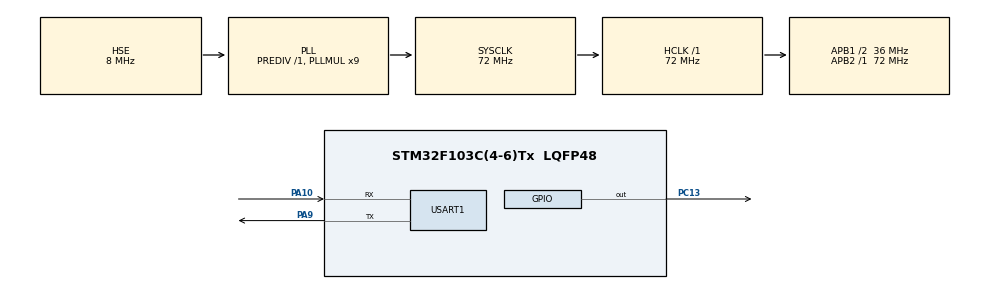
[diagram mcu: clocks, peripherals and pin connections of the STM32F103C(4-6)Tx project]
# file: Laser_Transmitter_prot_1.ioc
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Mcu.Family=STM32F1
Mcu.Name=STM32F103C(4-6)Tx
Mcu.Package=LQFP48
NVIC.PriorityGroup=NVIC_PRIORITYGROUP_4
NVIC.USART1_IRQn=true\:0\:0\:false\:false\:true\:true\:true\:true
PA10.Mode=Asynchronous
PA10.Signal=USART1_RX
PA9.Mode=Asynchronous
PA9.Signal=USART1_TX
PC13-TAMPER-RTC.Signal=GPIO_Output
PD0-OSC_IN.Mode=HSE-External-Oscillator
PD0-OSC_IN.Signal=RCC_OSC_IN
PD1-OSC_OUT.Mode=HSE-External-Oscillator
PD1-OSC_OUT.Signal=RCC_OSC_OUT
ProjectManager.HeapSize=0x200
ProjectManager.StackSize=0x400
ProjectManager.TargetToolchain=STM32CubeIDE
RCC.AHBFreq_Value=72000000
RCC.APB1CLKDivider=RCC_HCLK_DIV2
RCC.APB1Freq_Value=36000000
RCC.APB1TimFreq_Value=72000000
RCC.APB2Freq_Value=72000000
RCC.APB2TimFreq_Value=72000000
RCC.HCLKFreq_Value=72000000
RCC.PLLMUL=RCC_PLL_MUL9
RCC.PLLSourceVirtual=RCC_PLLSOURCE_HSE
RCC.SYSCLKFreq_VALUE=72000000
RCC.SYSCLKSource=RCC_SYSCLKSOURCE_PLLCLK
RCC.USBFreq_Value=72000000
USART1.VirtualMode=VM_ASYNC
VP_SYS_VS_ND.Mode=No_Debug
board=custom

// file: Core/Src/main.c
/* USER CODE BEGIN Header */
/**
  ******************************************************************************
  * @file           : main.c
  * @brief          : Main program body
  ******************************************************************************
  * @attention
  *
  * Copyright (c) 2025 STMicroelectronics.
  * All rights reserved.
  *
  * This software is licensed under terms that can be found in the LICENSE file
  * in the root directory of this software component.
  * If no LICENSE file comes with this software, it is provided AS-IS.
  *
  ******************************************************************************
  */
/* USER CODE END Header */
#include "main.h"

UART_HandleTypeDef huart1;

/* USER CODE BEGIN PV */
char tx_buffer[32];
uint8_t cur_light;
uint8_t rx_indx;
uint8_t rx_data[1];
uint8_t rx_buffer[100];
uint8_t transfer_cplt;
/* USER CODE END PV */

void SystemClock_Config(void);
static void MX_GPIO_Init(void);
static void MX_USART1_UART_Init(void);
/* USER CODE BEGIN PFP */
static void Transmit_message_OOK(uint8_t*, uint8_t);
static void Transmit_message_PPM(uint8_t*, uint8_t);
/* USER CODE END PFP */

int main(void)
{

  /* MCU Configuration--------------------------------------------------------*/

  /* Reset of all peripherals, Initializes the Flash interface and the Systick. */
  HAL_Init();

  /* Configure the system clock */
  SystemClock_Config();

  /* Initialize all configured peripherals */
  MX_GPIO_Init();
  MX_USART1_UART_Init();
  /* USER CODE BEGIN 2 */

  HAL_UART_Receive_IT(&huart1, rx_data, 1);
  /* USER CODE END 2 */

  /* Infinite loop */
  /* USER CODE BEGIN WHILE */
  while (1)
  {
	  HAL_UART_Transmit(&huart1, (unsigned char *)"Please, insert your message\n\r",29 , 10);

	  while (transfer_cplt != 1){
		  HAL_Delay(100);
	  }

	  HAL_UART_Transmit(&huart1, (unsigned char *)"Starting transmission", 21, 5);
	  Transmit_message_PPM(rx_buffer, 100);
	  HAL_Delay(160);
	  HAL_UART_Transmit(&huart1, (unsigned char *)"\n\rTransmission complete\n\r", 25, 5);
	  HAL_GPIO_WritePin(GPIOC, GPIO_PIN_13, 0);
	  transfer_cplt = 0;

	  /*
	  HAL_GPIO_WritePin(GPIOC, GPIO_PIN_13, 1);
	  HAL_Delay(5000);
	  HAL_GPIO_WritePin(GPIOC, GPIO_PIN_13, 0);
	  HAL_Delay(1000);
	  HAL_UART_Transmit(&huart1, "Hello, world!", 13, 5);
	  */
    /* USER CODE END WHILE */

  }
}

void SystemClock_Config(void)
{
  RCC_OscInitTypeDef RCC_OscInitStruct = {0};
  RCC_ClkInitTypeDef RCC_ClkInitStruct = {0};

  /** Initializes the RCC Oscillators according to the specified parameters
  * in the RCC_OscInitTypeDef structure.
  */
  RCC_OscInitStruct.OscillatorType = RCC_OSCILLATORTYPE_HSE;
  RCC_OscInitStruct.HSEState = RCC_HSE_ON;
  RCC_OscInitStruct.HSEPredivValue = RCC_HSE_PREDIV_DIV1;
  RCC_OscInitStruct.HSIState = RCC_HSI_ON;
  RCC_OscInitStruct.PLL.PLLState = RCC_PLL_ON;
  RCC_OscInitStruct.PLL.PLLSource = RCC_PLLSOURCE_HSE;
  RCC_OscInitStruct.PLL.PLLMUL = RCC_PLL_MUL9;
  if (HAL_RCC_OscConfig(&RCC_OscInitStruct) != HAL_OK)
  {
    Error_Handler();
  }

  /** Initializes the CPU, AHB and APB buses clocks
  */
  RCC_ClkInitStruct.ClockType = RCC_CLOCKTYPE_HCLK|RCC_CLOCKTYPE_SYSCLK
                              |RCC_CLOCKTYPE_PCLK1|RCC_CLOCKTYPE_PCLK2;
  RCC_ClkInitStruct.SYSCLKSource = RCC_SYSCLKSOURCE_PLLCLK;
  RCC_ClkInitStruct.AHBCLKDivider = RCC_SYSCLK_DIV1;
  RCC_ClkInitStruct.APB1CLKDivider = RCC_HCLK_DIV2;
  RCC_ClkInitStruct.APB2CLKDivider = RCC_HCLK_DIV1;

  if (HAL_RCC_ClockConfig(&RCC_ClkInitStruct, FLASH_LATENCY_2) != HAL_OK)
  {
    Error_Handler();
  }
}

static void MX_USART1_UART_Init(void)
{

  huart1.Instance = USART1;
  huart1.Init.BaudRate = 115200;
  huart1.Init.WordLength = UART_WORDLENGTH_8B;
  huart1.Init.StopBits = UART_STOPBITS_1;
  huart1.Init.Parity = UART_PARITY_NONE;
  huart1.Init.Mode = UART_MODE_TX_RX;
  huart1.Init.HwFlowCtl = UART_HWCONTROL_NONE;
  huart1.Init.OverSampling = UART_OVERSAMPLING_16;
  if (HAL_UART_Init(&huart1) != HAL_OK)
  {
    Error_Handler();
  }

}

static void MX_GPIO_Init(void)
{
  GPIO_InitTypeDef GPIO_InitStruct = {0};

  /* GPIO Ports Clock Enable */
  __HAL_RCC_GPIOC_CLK_ENABLE();
  __HAL_RCC_GPIOD_CLK_ENABLE();
  __HAL_RCC_GPIOA_CLK_ENABLE();

  /*Configure GPIO pin Output Level */
  HAL_GPIO_WritePin(GPIOC, GPIO_PIN_13, GPIO_PIN_RESET);

  /*Configure GPIO pin : PC13 */
  GPIO_InitStruct.Pin = GPIO_PIN_13;
  GPIO_InitStruct.Mode = GPIO_MODE_OUTPUT_PP;
  GPIO_InitStruct.Pull = GPIO_NOPULL;
  GPIO_InitStruct.Speed = GPIO_SPEED_FREQ_LOW;
  HAL_GPIO_Init(GPIOC, &GPIO_InitStruct);

}

/* USER CODE BEGIN 4 */
static void Transmit_message_OOK(uint8_t* message, uint8_t n){
	for (uint8_t i = 0; i < n; i++){
		HAL_UART_Transmit(&huart1, (unsigned char *)".", 1, 5);
		if (message[i] == 49){
			HAL_GPIO_WritePin(GPIOC, GPIO_PIN_13, 1);
			HAL_Delay(10);
		}else if (message[i] == 48){
			HAL_GPIO_WritePin(GPIOC, GPIO_PIN_13, 0);
			HAL_Delay(10);
		}else{
			return;
		}
	}
}

static void Transmit_message_PPM(uint8_t* message, uint8_t n){
	HAL_GPIO_WritePin(GPIOC, GPIO_PIN_13, 1);
	HAL_Delay(10);
	HAL_GPIO_WritePin(GPIOC, GPIO_PIN_13, 0);
	for (uint8_t i = 0; i < n; i+=2){
		//HAL_UART_Transmit(&huart1, (uint8_t*)"..", 2, 5);
		if (message[i] == 48 && message[i + 1] == 48){
			HAL_GPIO_WritePin(GPIOC, GPIO_PIN_13, 1);
			HAL_Delay(10);
			HAL_GPIO_WritePin(GPIOC, GPIO_PIN_13, 0);
			HAL_Delay(30);
		}else if (message[i] == 48 && message[i + 1] == 49){
			HAL_Delay(10);
			HAL_GPIO_WritePin(GPIOC, GPIO_PIN_13, 1);
			HAL_Delay(10);
			HAL_GPIO_WritePin(GPIOC, GPIO_PIN_13, 0);
			HAL_Delay(20);
		}else if(message[i] == 49 && message[i + 1] == 48){
			HAL_Delay(20);
			HAL_GPIO_WritePin(GPIOC, GPIO_PIN_13, 1);
			HAL_Delay(10);
			HAL_GPIO_WritePin(GPIOC, GPIO_PIN_13, 0);
			HAL_Delay(10);
		}else if(message[i] == 49 && message[i + 1] == 49){
			HAL_Delay(30);
			HAL_GPIO_WritePin(GPIOC, GPIO_PIN_13, 1);
			HAL_Delay(10);
			HAL_GPIO_WritePin(GPIOC, GPIO_PIN_13, 0);
		}
		/*
		else{
			for (int i = 0; i < 8; i++){
				HAL_GPIO_WritePin(GPIOC, GPIO_PIN_13, 1);
				HAL_Delay(10);
				HAL_GPIO_WritePin(GPIOC, GPIO_PIN_13, 0);
				HAL_Delay(30);
			}
			return;
		}
		*/
	}

}

void HAL_UART_RxCpltCallback(UART_HandleTypeDef *huart)
{
  /* Prevent unused argument(s) compilation warning */
  UNUSED(huart);

  /* NOTE : This function should not be modified, when the callback is needed,
            the HAL_UART_RxCpltCallback can be implemented in the user file.
   */
  if (huart->Instance == USART1){
	  //HAL_UART_Transmit(&huart1, "puk", 3, 10);
	  if (rx_indx == 0){
		  for (uint8_t i = 0; i < 100; i++){
			  rx_buffer[i] = 2;
		  }
	  }
	  if (*rx_data != 13){
		  rx_buffer[rx_indx++] = rx_data[0];
	  }else{
		  rx_indx = 0;
		  transfer_cplt = 1;
		  //rx_buffer[rx_indx++] = 5;
		  HAL_UART_Transmit(&huart1, (unsigned char *)"\n\r", 2, 5);
	  }

	  HAL_UART_Receive_IT(&huart1, rx_data, 1);
	  HAL_UART_Transmit(&huart1, rx_data, 1, 5);
  }
}
/* USER CODE END 4 */

void Error_Handler(void)
{
  __disable_irq();
  while (1)
  {
  }
}
